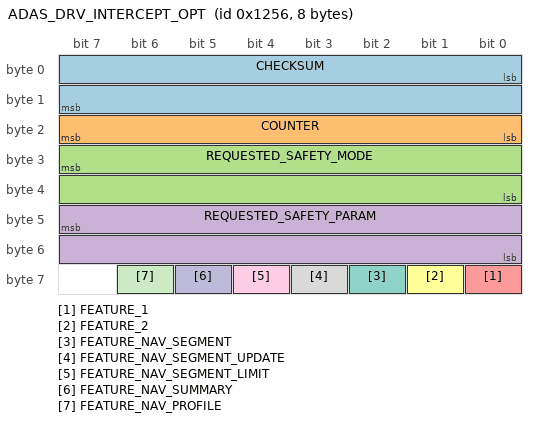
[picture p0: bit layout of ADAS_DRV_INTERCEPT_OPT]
BO_ 4694 ADAS_DRV_INTERCEPT_OPT: 8 SP
 SG_ CHECKSUM : 0|16@1+ (1,0) [0|0] "0" interceptor
 SG_ COUNTER : 16|8@1+ (1,0) [0|0] "0" interceptor
 SG_ REQUESTED_SAFETY_MODE : 31|16@0+ (1,0) [0|65535] "" interceptor
 SG_ REQUESTED_SAFETY_PARAM : 47|16@0+ (1,0) [0|65535] "" interceptor
 SG_ FEATURE_1 : 56|1@1+ (1,0) [0|1] "" interceptor
 SG_ FEATURE_2 : 57|1@1+ (1,0) [0|1] "" interceptor
 SG_ FEATURE_NAV_SEGMENT : 58|1@1+ (1,0) [0|1] "" interceptor
 SG_ FEATURE_NAV_SEGMENT_UPDATE : 59|1@1+ (1,0) [0|1] "" interceptor
 SG_ FEATURE_NAV_SEGMENT_LIMIT : 60|1@1+ (1,0) [0|1] "" interceptor
 SG_ FEATURE_NAV_SUMMARY : 61|1@1+ (1,0) [0|1] "" interceptor
 SG_ FEATURE_NAV_PROFILE : 62|1@1+ (1,0) [0|1] "" interceptor

BO_ 4696 INTERCEPTOR_HEARTBEAT: 64 interceptor
 SG_ CHECKSUM : 0|16@1+ (1,0) [0|0] "0" SP
 SG_ COUNTER : 16|8@1+ (1,0) [0|0] "0" SP
 SG_ CURRENT_SAFETY_MODE : 31|16@0+ (1,0) [0|65535] "" SP
 SG_ CURRENT_SAFETY_PARAM : 47|16@0+ (1,0) [0|65535] "" SP
 SG_ SP_SEEN_RECENTLY : 57|2@0+ (1,0) [0|3] "" SP
 SG_ NAV_PROFILE_REWRITES : 58|6@1+ (1,0) [0|63] "" SP
 SG_ CAN_RX_R : 71|16@0+ (1,0) [0|65535] "" SP
 SG_ CAN_RX_W : 87|16@0+ (1,0) [0|65535] "" SP
 SG_ CAN_TX1_R : 103|16@0+ (1,0) [0|65535] "" SP
 SG_ CAN_TX1_W : 119|16@0+ (1,0) [0|65535] "" SP
 SG_ CAN_TX2_R : 135|16@0+ (1,0) [0|65535] "" SP
 SG_ CAN_TX2_W : 151|16@0+ (1,0) [0|65535] "" SP
 SG_ CAN_TX3_R : 167|16@0+ (1,0) [0|65535] "" SP
 SG_ CAN_TX3_W : 183|16@0+ (1,0) [0|65535] "" SP
 SG_ TAMPER_HOOK_CALL_COUNT : 199|32@0+ (1,0) [0|4294967295] "" SP
 SG_ RX_HOOK_BUS_0_COUNT : 231|32@0+ (1,0) [0|4294967295] "" SP
 SG_ RX_HOOK_BUS_1_COUNT : 263|32@0+ (1,0) [0|4294967295] "" SP
 SG_ RX_HOOK_BUS_2_COUNT : 295|32@0+ (1,0) [0|4294967295] "" SP
 SG_ CAN_0_TEC : 327|8@0+ (1,0) [0|255] "" SP
 SG_ CAN_0_REC : 335|8@0+ (1,0) [0|255] "" SP
 SG_ CAN_0_BUS_OFF_CNT : 343|16@0+ (1,0) [0|65535] "" SP
 SG_ CAN_1_TEC : 359|8@0+ (1,0) [0|255] "" SP
 SG_ CAN_1_REC : 367|8@0+ (1,0) [0|255] "" SP
 SG_ CAN_1_BUS_OFF_CNT : 375|16@0+ (1,0) [0|65535] "" SP
 SG_ CAN_2_TEC : 391|8@0+ (1,0) [0|255] "" SP
 SG_ CAN_2_REC : 399|8@0+ (1,0) [0|255] "" SP
 SG_ CAN_2_BUS_OFF_CNT : 407|16@0+ (1,0) [0|65535] "" SP
 SG_ CAN_0_TX_LOST : 423|32@0+ (1,0) [0|4294967295] "" SP
 SG_ CAN_2_TX_LOST : 455|32@0+ (1,0) [0|4294967295] "" SP
 SG_ CURRENT_FEATURE_1 : 480|1@1+ (1,0) [0|1] "" SP
 SG_ CURRENT_FEATURE_2 : 481|1@1+ (1,0) [0|1] "" SP
 SG_ CURRENT_FEATURE_NAV_SEGMENT : 482|1@1+ (1,0) [0|1] "" SP
 SG_ CURRENT_FEATURE_NAV_SEGMENT_UPDATE : 483|1@1+ (1,0) [0|1] "" SP
 SG_ CURRENT_FEATURE_NAV_SEGMENT_LIMIT : 484|1@1+ (1,0) [0|1] "" SP
 SG_ CURRENT_FEATURE_NAV_SUMMARY : 485|1@1+ (1,0) [0|1] "" SP
 SG_ CURRENT_FEATURE_NAV_PROFILE : 486|1@1+ (1,0) [0|1] "" SP
 SG_ NAV_SEGMENT_REWRITES : 488|8@1+ (1,0) [0|255] "" SP
 SG_ NAV_SEGMENT_UPDATE_REWRITES : 496|8@1+ (1,0) [0|255] "" SP
 SG_ NAV_SUMMARY_REWRITES : 504|8@1+ (1,0) [0|255] "" SP
